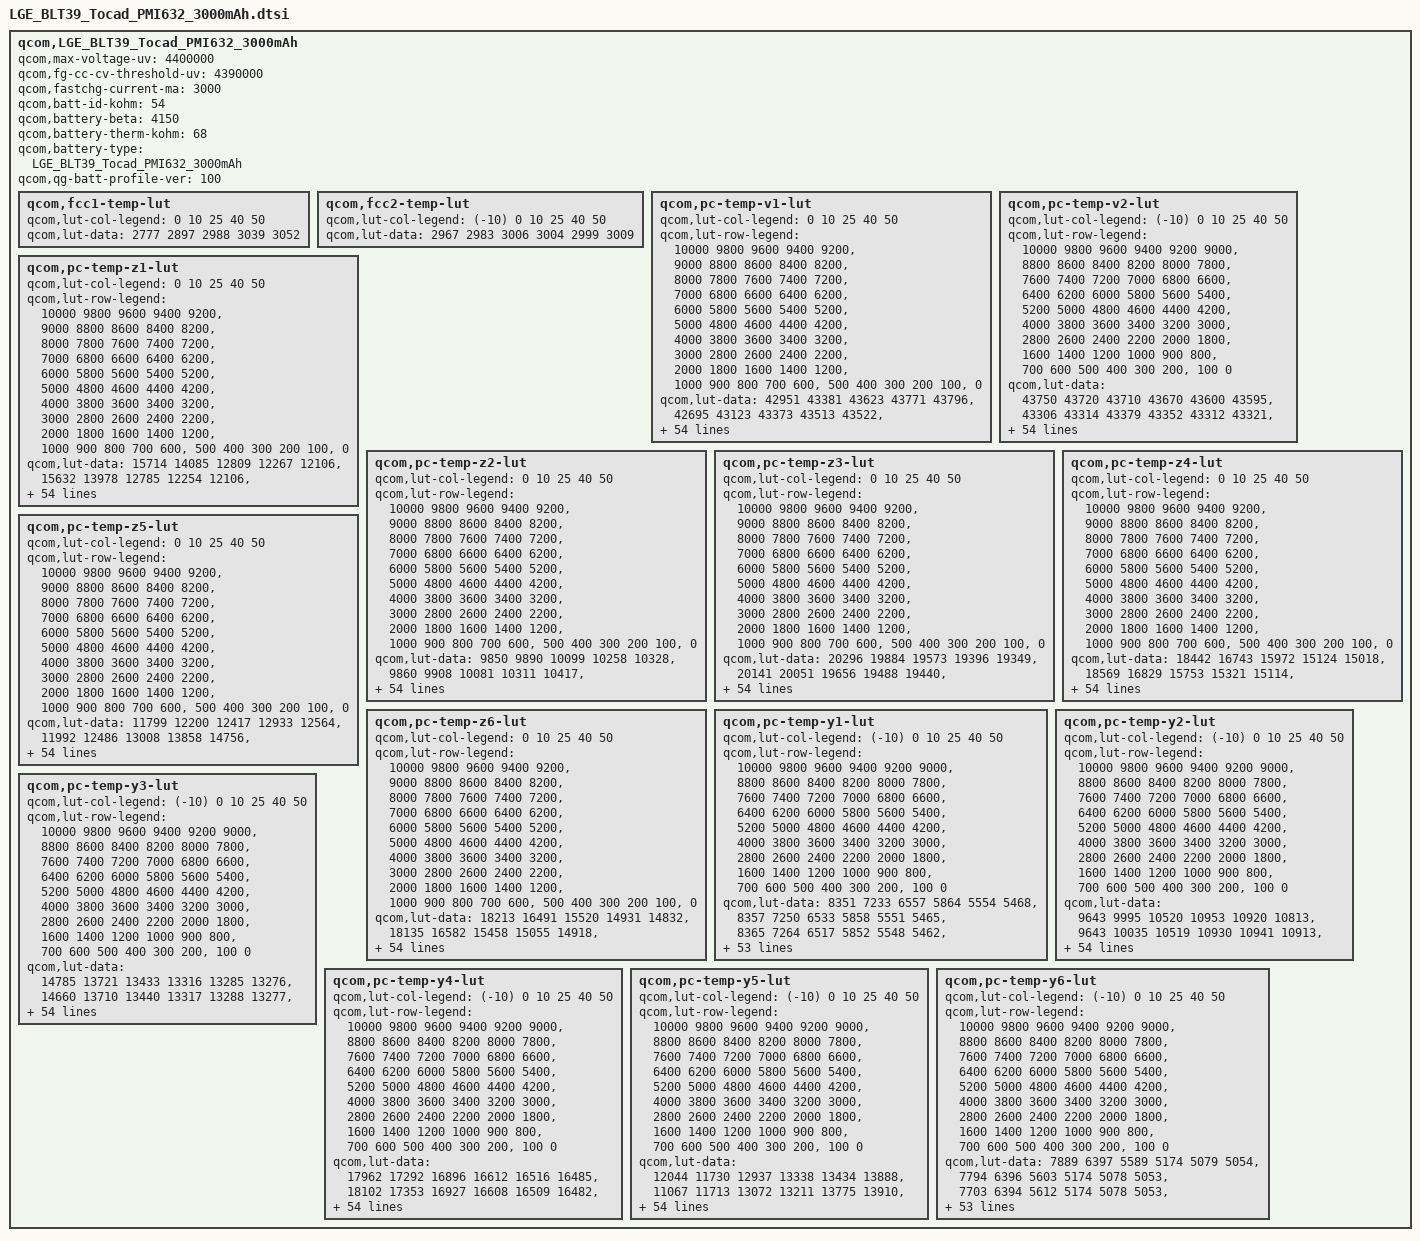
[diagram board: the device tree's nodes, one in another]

qcom,LGE_BLT39_Tocad_PMI632_3000mAh {
    /* 3869834_LGE_BLT39atl_3000mAh_averaged_MasterSlave_Feb20th2019 */
    qcom,max-voltage-uv = <4400000>;
    qcom,fg-cc-cv-threshold-uv = <4390000>;
    qcom,fastchg-current-ma = <3000>;
    qcom,batt-id-kohm = <54>;
    qcom,battery-beta = <4150>;
    qcom,battery-therm-kohm = <68>;
    qcom,battery-type = "LGE_BLT39_Tocad_PMI632_3000mAh";
    qcom,qg-batt-profile-ver = <100>;

	qcom,fcc1-temp-lut {
		qcom,lut-col-legend = <0 10 25 40 50>;
		qcom,lut-data = <2777 2897 2988 3039 3052>;
	};

	qcom,fcc2-temp-lut {
		qcom,lut-col-legend = <(-10) 0 10 25 40 50>;
		qcom,lut-data = <2967 2983 3006 3004 2999 3009>;
	};

	qcom,pc-temp-v1-lut {
		qcom,lut-col-legend = <0 10 25 40 50>;
		qcom,lut-row-legend = <10000 9800 9600 9400 9200>,
			<9000 8800 8600 8400 8200>,
			<8000 7800 7600 7400 7200>,
			<7000 6800 6600 6400 6200>,
			<6000 5800 5600 5400 5200>,
			<5000 4800 4600 4400 4200>,
			<4000 3800 3600 3400 3200>,
			<3000 2800 2600 2400 2200>,
			<2000 1800 1600 1400 1200>,
			<1000 900 800 700 600>,
			<500 400 300 200 100>,
			<0>;
		qcom,lut-data = <42951 43381 43623 43771 43796>,
			<42695 43123 43373 43513 43522>,
			<42449 42883 43126 43271 43280>,
			<42209 42651 42885 43035 43048>,
			<41979 42422 42647 42798 42815>,
			<41758 42196 42412 42561 42583>,
			<41545 41974 42180 42327 42350>,
			<41343 41754 41951 42094 42115>,
			<41159 41539 41724 41863 41882>,
			<40978 41334 41500 41634 41654>,
			<40774 41143 41282 41407 41429>,
			<40540 40950 41073 41187 41210>,
			<40315 40734 40869 40972 40994>,
			<40123 40504 40666 40766 40786>,
			<39947 40301 40463 40565 40581>,
			<39797 40124 40272 40372 40383>,
			<39672 39964 40100 40188 40196>,
			<39561 39819 39936 40012 40019>,
			<39454 39687 39779 39844 39849>,
			<39349 39555 39630 39694 39695>,
			<39250 39419 39477 39542 39544>,
			<39153 39281 39322 39343 39349>,
			<39058 39141 39158 39088 39083>,
			<38969 38998 38959 38878 38862>,
			<38888 38853 38715 38727 38730>,
			<38811 38695 38546 38605 38626>,
			<38731 38538 38466 38508 38525>,
			<38643 38429 38408 38430 38428>,
			<38556 38356 38356 38353 38339>,
			<38475 38303 38314 38273 38253>,
			<38390 38272 38270 38199 38176>,
			<38323 38251 38217 38137 38109>,
			<38281 38230 38164 38083 38052>,
			<38250 38207 38120 38033 37998>,
			<38219 38183 38084 37990 37951>,
			<38190 38157 38047 37947 37903>,
			<38158 38130 38010 37903 37845>,
			<38118 38093 37969 37856 37779>,
			<38064 38031 37908 37795 37706>,
			<37996 37939 37813 37708 37627>,
			<37898 37836 37706 37605 37538>,
			<37762 37712 37592 37494 37428>,
			<37614 37570 37461 37366 37297>,
			<37460 37400 37298 37206 37138>,
			<37342 37260 37152 37058 36994>,
			<37238 37163 37066 36972 36909>,
			<37202 37134 37040 36950 36891>,
			<37171 37109 37024 36936 36876>,
			<37139 37081 37002 36918 36857>,
			<37068 37030 36955 36871 36803>,
			<36840 36807 36720 36628 36534>,
			<36388 36359 36285 36197 36096>,
			<35813 35786 35713 35628 35520>,
			<35039 35003 34933 34851 34733>,
			<33776 33770 33713 33650 33503>,
			<30000 30000 30000 30000 30000>;
	};

	qcom,pc-temp-v2-lut {
		qcom,lut-col-legend = <(-10) 0 10 25 40 50>;
		qcom,lut-row-legend = <10000 9800 9600 9400 9200 9000>,
			<8800 8600 8400 8200 8000 7800>,
			<7600 7400 7200 7000 6800 6600>,
			<6400 6200 6000 5800 5600 5400>,
			<5200 5000 4800 4600 4400 4200>,
			<4000 3800 3600 3400 3200 3000>,
			<2800 2600 2400 2200 2000 1800>,
			<1600 1400 1200 1000 900 800>,
			<700 600 500 400 300 200>,
			<100 0>;
		qcom,lut-data = <43750 43720 43710 43670 43600 43595>,
			<43306 43314 43379 43352 43312 43321>,
			<42915 42955 43073 43059 43041 43059>,
			<42583 42651 42797 42796 42789 42811>,
			<42299 42391 42550 42559 42555 42577>,
			<42046 42152 42311 42329 42326 42346>,
			<41815 41930 42070 42097 42095 42115>,
			<41603 41718 41834 41868 41867 41886>,
			<41405 41484 41604 41644 41643 41661>,
			<41222 41219 41378 41424 41421 41437>,
			<41034 40990 41163 41209 41203 41218>,
			<40833 40842 40968 40997 40989 41005>,
			<40617 40717 40779 40789 40779 40796>,
			<40350 40518 40574 40585 40578 40595>,
			<39984 40187 40353 40380 40383 40397>,
			<39645 39872 40138 40186 40195 40207>,
			<39430 39666 39942 40011 40018 40028>,
			<39261 39493 39750 39844 39847 39855>,
			<39093 39308 39547 39682 39684 39691>,
			<38921 39111 39331 39531 39533 39538>,
			<38760 38922 39128 39360 39364 39367>,
			<38611 38749 38942 39127 39137 39141>,
			<38473 38588 38771 38880 38894 38907>,
			<38360 38440 38621 38702 38717 38733>,
			<38268 38294 38486 38565 38582 38593>,
			<38190 38180 38366 38447 38466 38472>,
			<38125 38110 38262 38342 38362 38367>,
			<38069 38058 38167 38249 38269 38274>,
			<38014 38009 38073 38162 38184 38187>,
			<37960 37966 37979 38083 38106 38106>,
			<37908 37925 37907 38012 38035 38033>,
			<37854 37881 37859 37944 37970 37967>,
			<37801 37837 37821 37883 37911 37905>,
			<37744 37790 37784 37823 37849 37845>,
			<37685 37741 37752 37768 37789 37790>,
			<37624 37690 37715 37713 37721 37720>,
			<37560 37636 37672 37660 37636 37611>,
			<37496 37578 37623 37604 37541 37489>,
			<37431 37513 37567 37541 37459 37398>,
			<37368 37438 37506 37470 37387 37323>,
			<37304 37355 37429 37389 37308 37241>,
			<37239 37255 37308 37286 37210 37143>,
			<37172 37143 37172 37166 37095 37029>,
			<37097 37034 37035 37018 36950 36891>,
			<37012 36936 36902 36897 36841 36781>,
			<36905 36849 36816 36839 36798 36747>,
			<36846 36807 36784 36826 36785 36737>,
			<36775 36767 36752 36803 36767 36719>,
			<36685 36718 36707 36772 36738 36682>,
			<36555 36637 36624 36684 36656 36567>,
			<36334 36442 36416 36389 36357 36231>,
			<35963 36037 35982 35887 35877 35724>,
			<35400 35432 35367 35250 35253 35067>,
			<34548 34578 34528 34357 34386 34157>,
			<33078 33229 33255 32986 33060 32722>,
			<28333 28048 27993 28115 29232 28098>;
	};

	qcom,pc-temp-z1-lut {
		qcom,lut-col-legend = <0 10 25 40 50>;
		qcom,lut-row-legend = <10000 9800 9600 9400 9200>,
			<9000 8800 8600 8400 8200>,
			<8000 7800 7600 7400 7200>,
			<7000 6800 6600 6400 6200>,
			<6000 5800 5600 5400 5200>,
			<5000 4800 4600 4400 4200>,
			<4000 3800 3600 3400 3200>,
			<3000 2800 2600 2400 2200>,
			<2000 1800 1600 1400 1200>,
			<1000 900 800 700 600>,
			<500 400 300 200 100>,
			<0>;
		qcom,lut-data = <15714 14085 12809 12267 12106>,
			<15632 13978 12785 12254 12106>,
			<15579 13970 12765 12243 12102>,
			<15532 13966 12749 12232 12098>,
			<15503 13956 12736 12225 12097>,
			<15495 13939 12724 12219 12096>,
			<15494 13927 12712 12216 12095>,
			<15492 13922 12704 12214 12093>,
			<15474 13920 12703 12213 12092>,
			<15444 13923 12703 12212 12092>,
			<15409 13937 12703 12211 12093>,
			<15344 13950 12702 12211 12093>,
			<15278 13940 12702 12211 12094>,
			<15237 13914 12700 12211 12096>,
			<15203 13897 12695 12211 12098>,
			<15174 13888 12693 12212 12099>,
			<15148 13881 12698 12214 12101>,
			<15127 13884 12705 12217 12104>,
			<15111 13894 12708 12220 12106>,
			<15099 13907 12710 12222 12109>,
			<15091 13922 12714 12225 12112>,
			<15096 13937 12721 12228 12114>,
			<15116 13941 12729 12231 12117>,
			<15140 13936 12733 12235 12120>,
			<15173 13933 12736 12240 12124>,
			<15215 13944 12740 12245 12129>,
			<15239 13965 12751 12250 12134>,
			<15257 13980 12763 12255 12139>,
			<15271 13990 12769 12261 12144>,
			<15273 13996 12772 12267 12150>,
			<15280 13991 12775 12273 12155>,
			<15292 13977 12780 12279 12159>,
			<15333 13971 12786 12284 12163>,
			<15402 13978 12792 12288 12167>,
			<15438 13987 12798 12292 12170>,
			<15443 13996 12804 12296 12173>,
			<15441 14006 12810 12301 12177>,
			<15440 14016 12816 12305 12180>,
			<15433 14028 12825 12310 12183>,
			<15427 14041 12839 12315 12187>,
			<15433 14054 12850 12320 12191>,
			<15446 14073 12856 12326 12195>,
			<15425 14080 12861 12331 12199>,
			<15381 14076 12867 12338 12203>,
			<15370 14053 12882 12346 12209>,
			<15357 14038 12892 12351 12214>,
			<15364 14052 12884 12353 12215>,
			<15332 14017 12890 12356 12217>,
			<15336 14021 12894 12360 12221>,
			<15375 14026 12904 12365 12226>,
			<15384 14058 12907 12375 12233>,
			<15365 14093 12930 12387 12245>,
			<15406 14129 12974 12408 12262>,
			<15420 14198 13009 12435 12284>,
			<15420 14198 13009 12435 12284>,
			<15420 14198 13009 12435 12284>;
	};

	qcom,pc-temp-z2-lut {
		qcom,lut-col-legend = <0 10 25 40 50>;
		qcom,lut-row-legend = <10000 9800 9600 9400 9200>,
			<9000 8800 8600 8400 8200>,
			<8000 7800 7600 7400 7200>,
			<7000 6800 6600 6400 6200>,
			<6000 5800 5600 5400 5200>,
			<5000 4800 4600 4400 4200>,
			<4000 3800 3600 3400 3200>,
			<3000 2800 2600 2400 2200>,
			<2000 1800 1600 1400 1200>,
			<1000 900 800 700 600>,
			<500 400 300 200 100>,
			<0>;
		qcom,lut-data = <9850 9890 10099 10258 10328>,
			<9860 9908 10081 10311 10417>,
			<9859 9913 10060 10290 10404>,
			<9849 9918 10032 10260 10381>,
			<9840 9933 9996 10225 10358>,
			<9838 9974 9980 10186 10329>,
			<9836 9999 9980 10180 10318>,
			<9835 9997 9980 10202 10335>,
			<9833 9992 9986 10228 10358>,
			<9830 9984 10002 10248 10370>,
			<9823 9963 10018 10267 10381>,
			<9805 9936 10031 10281 10379>,
			<9791 9900 10044 10295 10307>,
			<9791 9857 10059 10301 10241>,
			<9792 9842 10076 10270 10242>,
			<9794 9843 10090 10220 10254>,
			<9800 9846 10098 10216 10271>,
			<9808 9852 10106 10236 10305>,
			<9816 9867 10117 10248 10327>,
			<9824 9881 10131 10238 10323>,
			<9833 9891 10138 10226 10314>,
			<9845 9901 10139 10249 10325>,
			<9861 9910 10140 10339 10401>,
			<9880 9919 10134 10383 10452>,
			<9907 9927 10108 10290 10402>,
			<9939 9933 10095 10177 10329>,
			<9959 9939 10100 10219 10349>,
			<9981 9944 10111 10394 10482>,
			<9997 9952 10130 10470 10551>,
			<9989 9959 10168 10427 10473>,
			<9960 9962 10192 10369 10371>,
			<9931 9963 10200 10335 10342>,
			<9911 9965 10204 10307 10320>,
			<9893 9969 10201 10301 10313>,
			<9883 9974 10186 10333 10331>,
			<9877 9980 10177 10376 10363>,
			<9873 9988 10185 10406 10439>,
			<9877 9996 10202 10433 10580>,
			<9907 10006 10223 10463 10626>,
			<9936 10016 10256 10502 10574>,
			<9945 10027 10275 10528 10517>,
			<9951 10037 10275 10530 10493>,
			<9990 10051 10275 10531 10480>,
			<10047 10075 10292 10535 10490>,
			<9672 10250 10359 10558 10499>,
			<9668 10324 10390 10503 10496>,
			<9757 10394 10370 10467 10505>,
			<9775 10510 10395 10449 10483>,
			<9858 10578 10383 10445 10486>,
			<9922 10618 10390 10510 10631>,
			<9821 10545 10634 10783 10599>,
			<9652 10556 10603 10701 10491>,
			<9565 10286 10574 10650 10423>,
			<9400 10121 10523 10603 10333>,
			<9400 10121 10523 10603 10333>,
			<9400 10121 10523 10603 10333>;
	};

	qcom,pc-temp-z3-lut {
		qcom,lut-col-legend = <0 10 25 40 50>;
		qcom,lut-row-legend = <10000 9800 9600 9400 9200>,
			<9000 8800 8600 8400 8200>,
			<8000 7800 7600 7400 7200>,
			<7000 6800 6600 6400 6200>,
			<6000 5800 5600 5400 5200>,
			<5000 4800 4600 4400 4200>,
			<4000 3800 3600 3400 3200>,
			<3000 2800 2600 2400 2200>,
			<2000 1800 1600 1400 1200>,
			<1000 900 800 700 600>,
			<500 400 300 200 100>,
			<0>;
		qcom,lut-data = <20296 19884 19573 19396 19349>,
			<20141 20051 19656 19488 19440>,
			<20123 20068 19711 19524 19468>,
			<20142 20076 19726 19540 19480>,
			<20163 20057 19734 19545 19479>,
			<20178 19965 19736 19547 19470>,
			<20193 19887 19724 19545 19462>,
			<20198 19857 19702 19521 19457>,
			<20197 19836 19680 19498 19452>,
			<20197 19834 19655 19491 19443>,
			<20196 19848 19635 19486 19430>,
			<20196 19870 19621 19478 19414>,
			<20196 19900 19608 19465 19393>,
			<20186 19938 19595 19449 19378>,
			<20157 19951 19580 19423 19374>,
			<20122 19922 19568 19398 19373>,
			<20078 19880 19561 19393 19369>,
			<20024 19853 19555 19393 19358>,
			<19961 19830 19552 19393 19351>,
			<19878 19820 19550 19391 19351>,
			<19795 19823 19549 19390 19351>,
			<19731 19831 19558 19399 19356>,
			<19674 19842 19571 19437 19383>,
			<19629 19862 19577 19456 19400>,
			<19594 19881 19581 19437 19376>,
			<19565 19894 19583 19410 19341>,
			<19563 19904 19574 19396 19341>,
			<19734 19907 19559 19384 19364>,
			<19928 19903 19548 19382 19387>,
			<20003 19896 19538 19429 19409>,
			<20204 19886 19533 19480 19426>,
			<20342 19869 19560 19480 19424>,
			<20325 19853 19596 19468 19408>,
			<20289 19842 19599 19456 19396>,
			<20250 19832 19588 19445 19386>,
			<20204 19820 19575 19435 19379>,
			<20151 19804 19566 19428 19380>,
			<20089 19793 19558 19422 19383>,
			<20007 19789 19552 19419 19383>,
			<19949 19786 19548 19416 19376>,
			<19942 19782 19544 19413 19367>,
			<19945 19764 19539 19408 19364>,
			<19926 19743 19532 19402 19361>,
			<19850 19719 19521 19398 19358>,
			<19275 19608 19496 19394 19354>,
			<19267 19565 19471 19378 19353>,
			<19265 19516 19469 19376 19345>,
			<19264 19465 19448 19362 19341>,
			<19264 19445 19447 19361 19339>,
			<19263 19444 19443 19353 19329>,
			<19264 19473 19391 19326 19331>,
			<19266 19438 19368 19332 19338>,
			<19268 19377 19357 19328 19344>,
			<19273 19376 19349 19326 19351>,
			<19273 19376 19349 19326 19351>,
			<19273 19376 19349 19326 19351>;
	};

	qcom,pc-temp-z4-lut {
		qcom,lut-col-legend = <0 10 25 40 50>;
		qcom,lut-row-legend = <10000 9800 9600 9400 9200>,
			<9000 8800 8600 8400 8200>,
			<8000 7800 7600 7400 7200>,
			<7000 6800 6600 6400 6200>,
			<6000 5800 5600 5400 5200>,
			<5000 4800 4600 4400 4200>,
			<4000 3800 3600 3400 3200>,
			<3000 2800 2600 2400 2200>,
			<2000 1800 1600 1400 1200>,
			<1000 900 800 700 600>,
			<500 400 300 200 100>,
			<0>;
		qcom,lut-data = <18442 16743 15972 15124 15018>,
			<18569 16829 15753 15321 15114>,
			<18469 16568 15569 15227 15068>,
			<17967 16188 15422 15114 14995>,
			<17437 15998 15299 15043 14943>,
			<17107 15889 15201 14984 14899>,
			<16827 15791 15118 14946 14869>,
			<16598 15691 15053 14920 14850>,
			<16407 15594 15013 14899 14836>,
			<16248 15491 14986 14875 14825>,
			<16129 15376 14963 14853 14816>,
			<16037 15268 14942 14837 14810>,
			<15958 15173 14924 14823 14807>,
			<15885 15087 14911 14816 14804>,
			<15819 15049 14901 14817 14792>,
			<15764 15038 14889 14819 14772>,
			<15711 15031 14867 14815 14758>,
			<15670 15015 14842 14791 14748>,
			<15665 14992 14825 14769 14739>,
			<15705 14969 14811 14754 14726>,
			<15757 14945 14806 14743 14713>,
			<15800 14925 14810 14761 14728>,
			<15845 14922 14820 14846 14833>,
			<15877 14923 14869 14920 14922>,
			<15896 14926 15022 14974 14953>,
			<15909 14966 15103 15010 14972>,
			<15899 15045 15094 15009 14964>,
			<15698 15071 15075 14992 14913>,
			<15474 15068 15052 14965 14860>,
			<15385 15061 15021 14887 14809>,
			<15156 15046 14983 14808 14765>,
			<14990 15014 14927 14783 14747>,
			<14983 14984 14872 14768 14736>,
			<14980 14960 14849 14763 14732>,
			<14979 14939 14837 14762 14731>,
			<14988 14921 14831 14761 14731>,
			<15003 14903 14829 14765 14742>,
			<15023 14891 14827 14777 14770>,
			<15054 14885 14832 14790 14784>,
			<15077 14881 14856 14809 14789>,
			<15058 14877 14871 14821 14791>,
			<15014 14873 14853 14812 14784>,
			<14994 14870 14833 14799 14773>,
			<14984 14865 14830 14801 14779>,
			<15352 14847 14803 14788 14774>,
			<15348 14842 14767 14761 14744>,
			<15338 14876 14749 14741 14727>,
			<15327 14914 14739 14721 14699>,
			<15314 14923 14721 14692 14671>,
			<15294 14917 14723 14706 14691>,
			<15295 14897 14820 14781 14728>,
			<15338 14965 14859 14780 14723>,
			<15371 15054 14877 14785 14716>,
			<15400 15075 14891 14789 14710>,
			<15400 15075 14891 14789 14710>,
			<15400 15075 14891 14789 14710>;
	};

	qcom,pc-temp-z5-lut {
		qcom,lut-col-legend = <0 10 25 40 50>;
		qcom,lut-row-legend = <10000 9800 9600 9400 9200>,
			<9000 8800 8600 8400 8200>,
			<8000 7800 7600 7400 7200>,
			<7000 6800 6600 6400 6200>,
			<6000 5800 5600 5400 5200>,
			<5000 4800 4600 4400 4200>,
			<4000 3800 3600 3400 3200>,
			<3000 2800 2600 2400 2200>,
			<2000 1800 1600 1400 1200>,
			<1000 900 800 700 600>,
			<500 400 300 200 100>,
			<0>;
		qcom,lut-data = <11799 12200 12417 12933 12564>,
			<11992 12486 13008 13858 14756>,
			<12316 12681 13491 14415 15453>,
			<12819 12809 13837 14790 15824>,
			<13336 12785 14103 15150 15974>,
			<13766 12604 14351 15439 16064>,
			<14170 12487 14622 15495 16193>,
			<14550 12512 14857 15453 16485>,
			<14939 12580 15017 15420 16729>,
			<15280 12691 15175 15654 16638>,
			<15496 12998 15236 16070 16271>,
			<15667 13476 15356 16147 15823>,
			<15760 14465 15512 16013 15103>,
			<15740 15958 15525 15797 14585>,
			<15656 16488 15509 15119 14774>,
			<15532 16000 15573 14266 15222>,
			<15256 15452 16002 14219 15337>,
			<14817 15441 16711 14778 15214>,
			<14305 15702 17413 15417 15117>,
			<13584 16104 18197 15856 15407>,
			<12887 16946 19301 16426 16270>,
			<12441 18371 21708 19564 18306>,
			<12091 20380 24477 28881 24309>,
			<11833 23829 26024 33422 27991>,
			<11641 27241 27192 27465 23027>,
			<11492 29926 27617 19346 15564>,
			<11700 32225 25181 16300 14221>,
			<15800 32799 21360 14512 14175>,
			<20356 31799 19192 14056 14331>,
			<22161 30213 17587 16228 16203>,
			<27088 28429 16959 19265 18717>,
			<30595 26169 19318 21156 19799>,
			<29677 24669 22950 22697 20613>,
			<27228 23988 24497 23731 21191>,
			<24848 23487 25348 24527 22226>,
			<22406 22998 25739 24971 23142>,
			<19945 22468 25853 24682 23111>,
			<18007 22191 25909 23717 22750>,
			<16167 22941 25634 22529 22132>,
			<15099 24343 24301 20700 19735>,
			<15599 24573 23176 19121 17495>,
			<16748 22826 22753 18502 17088>,
			<16946 21768 22323 18035 16858>,
			<16525 21125 20763 17120 15875>,
			<11144 18519 20960 17294 15631>,
			<11044 16877 20168 17036 16460>,
			<11002 14701 20302 17394 16119>,
			<10989 13235 18091 16627 16981>,
			<10993 12896 18582 17926 19097>,
			<11028 12939 18240 16523 16410>,
			<11071 13751 13819 12926 13734>,
			<11062 12692 12739 12774 13779>,
			<10967 11752 12312 12481 13937>,
			<10903 11584 12006 12275 14288>,
			<10903 11584 12006 12275 14288>,
			<10903 11584 12006 12275 14288>;
	};

	qcom,pc-temp-z6-lut {
		qcom,lut-col-legend = <0 10 25 40 50>;
		qcom,lut-row-legend = <10000 9800 9600 9400 9200>,
			<9000 8800 8600 8400 8200>,
			<8000 7800 7600 7400 7200>,
			<7000 6800 6600 6400 6200>,
			<6000 5800 5600 5400 5200>,
			<5000 4800 4600 4400 4200>,
			<4000 3800 3600 3400 3200>,
			<3000 2800 2600 2400 2200>,
			<2000 1800 1600 1400 1200>,
			<1000 900 800 700 600>,
			<500 400 300 200 100>,
			<0>;
		qcom,lut-data = <18213 16491 15520 14931 14832>,
			<18135 16582 15458 15055 14918>,
			<17989 16462 15399 15030 14908>,
			<17741 16271 15343 14996 14889>,
			<17502 16138 15289 14971 14868>,
			<17336 16029 15239 14946 14845>,
			<17194 15937 15192 14923 14827>,
			<17076 15863 15151 14899 14816>,
			<16977 15801 15120 14878 14807>,
			<16892 15747 15094 14864 14796>,
			<16814 15701 15074 14852 14785>,
			<16745 15662 15057 14840 14774>,
			<16681 15632 15042 14827 14763>,
			<16622 15607 15028 14815 14753>,
			<16566 15585 15015 14803 14744>,
			<16512 15565 15002 14792 14735>,
			<16453 15547 14988 14782 14727>,
			<16399 15528 14976 14772 14718>,
			<16362 15510 14968 14765 14710>,
			<16334 15499 14962 14758 14704>,
			<16316 15496 14959 14752 14699>,
			<16307 15494 14965 14766 14709>,
			<16302 15495 14977 14825 14773>,
			<16300 15505 15007 14863 14815>,
			<16300 15521 15076 14874 14813>,
			<16301 15551 15110 14879 14809>,
			<16304 15592 15103 14876 14804>,
			<16318 15604 15090 14863 14797>,
			<16332 15603 15075 14852 14789>,
			<16337 15600 15057 14844 14780>,
			<16351 15591 15043 14837 14771>,
			<16360 15569 15036 14827 14760>,
			<16356 15550 15030 14816 14749>,
			<16346 15537 15023 14807 14740>,
			<16336 15526 15013 14799 14735>,
			<16325 15515 15005 14794 14731>,
			<16313 15504 15001 14795 14736>,
			<16300 15498 14998 14797 14751>,
			<16286 15499 15000 14800 14756>,
			<16272 15501 15010 14807 14755>,
			<16261 15501 15017 14812 14752>,
			<16249 15497 15009 14807 14748>,
			<16229 15492 14999 14798 14743>,
			<16190 15485 14996 14798 14744>,
			<16063 15432 14977 14793 14741>,
			<16059 15414 14953 14774 14728>,
			<16054 15406 14945 14764 14717>,
			<16051 15399 14931 14749 14703>,
			<16050 15397 14925 14737 14690>,
			<16052 15401 14927 14739 14694>,
			<16067 15421 14947 14760 14714>,
			<16104 15443 14959 14766 14718>,
			<16142 15471 14970 14771 14721>,
			<16192 15507 14986 14778 14727>,
			<16192 15507 14986 14778 14727>,
			<16192 15507 14986 14778 14727>;
	};

	qcom,pc-temp-y1-lut {
		qcom,lut-col-legend = <(-10) 0 10 25 40 50>;
		qcom,lut-row-legend = <10000 9800 9600 9400 9200 9000>,
			<8800 8600 8400 8200 8000 7800>,
			<7600 7400 7200 7000 6800 6600>,
			<6400 6200 6000 5800 5600 5400>,
			<5200 5000 4800 4600 4400 4200>,
			<4000 3800 3600 3400 3200 3000>,
			<2800 2600 2400 2200 2000 1800>,
			<1600 1400 1200 1000 900 800>,
			<700 600 500 400 300 200>,
			<100 0>;
		qcom,lut-data = <8351 7233 6557 5864 5554 5468>,
			<8357 7250 6533 5858 5551 5465>,
			<8365 7264 6517 5852 5548 5462>,
			<8373 7274 6507 5846 5545 5460>,
			<8380 7280 6501 5842 5543 5458>,
			<8384 7282 6498 5840 5541 5456>,
			<8385 7278 6501 5841 5539 5456>,
			<8386 7271 6507 5843 5537 5457>,
			<8383 7272 6508 5842 5536 5456>,
			<8358 7285 6503 5834 5534 5453>,
			<8339 7294 6499 5828 5532 5451>,
			<8339 7288 6492 5826 5531 5451>,
			<8341 7277 6483 5824 5530 5451>,
			<8344 7276 6485 5823 5530 5451>,
			<8357 7288 6499 5821 5529 5452>,
			<8368 7299 6507 5820 5529 5453>,
			<8366 7304 6503 5822 5530 5453>,
			<8359 7307 6496 5826 5531 5454>,
			<8356 7307 6495 5829 5532 5456>,
			<8363 7297 6496 5830 5533 5457>,
			<8369 7288 6497 5831 5535 5458>,
			<8357 7288 6499 5832 5536 5459>,
			<8332 7287 6502 5834 5537 5459>,
			<8324 7287 6506 5837 5539 5460>,
			<8360 7289 6515 5844 5541 5463>,
			<8398 7290 6521 5849 5543 5465>,
			<8382 7300 6523 5852 5546 5466>,
			<8332 7317 6525 5854 5550 5468>,
			<8308 7321 6526 5857 5552 5470>,
			<8304 7312 6529 5863 5554 5473>,
			<8302 7304 6530 5869 5557 5476>,
			<8305 7298 6527 5873 5562 5479>,
			<8320 7287 6524 5877 5568 5482>,
			<8326 7284 6527 5882 5573 5484>,
			<8314 7287 6539 5889 5578 5488>,
			<8297 7289 6547 5895 5582 5491>,
			<8295 7287 6554 5901 5585 5496>,
			<8305 7281 6560 5906 5588 5500>,
			<8311 7279 6559 5911 5591 5501>,
			<8312 7278 6549 5915 5594 5502>,
			<8315 7278 6544 5921 5599 5504>,
			<8324 7278 6546 5927 5604 5506>,
			<8349 7277 6551 5937 5609 5509>,
			<8330 7277 6562 5958 5614 5512>,
			<8277 7281 6560 5963 5618 5517>,
			<8297 7293 6566 5970 5622 5518>,
			<8336 7306 6580 5963 5623 5522>,
			<8325 7308 6587 5969 5627 5524>,
			<8351 7300 6588 5976 5631 5523>,
			<8331 7304 6575 5983 5633 5525>,
			<8336 7333 6593 6000 5637 5531>,
			<8405 7350 6608 6019 5649 5538>,
			<8408 7350 6608 6046 5665 5551>,
			<8497 7395 6645 6082 5686 5565>,
			<8497 7395 6645 6082 5686 5565>,
			<8497 7395 6645 6082 5686 5565>;
	};

	qcom,pc-temp-y2-lut {
		qcom,lut-col-legend = <(-10) 0 10 25 40 50>;
		qcom,lut-row-legend = <10000 9800 9600 9400 9200 9000>,
			<8800 8600 8400 8200 8000 7800>,
			<7600 7400 7200 7000 6800 6600>,
			<6400 6200 6000 5800 5600 5400>,
			<5200 5000 4800 4600 4400 4200>,
			<4000 3800 3600 3400 3200 3000>,
			<2800 2600 2400 2200 2000 1800>,
			<1600 1400 1200 1000 900 800>,
			<700 600 500 400 300 200>,
			<100 0>;
		qcom,lut-data = <9643 9995 10520 10953 10920 10813>,
			<9643 10035 10519 10930 10941 10913>,
			<9643 10090 10516 10894 10955 10969>,
			<9723 10145 10510 10855 10961 10993>,
			<9847 10188 10504 10822 10962 10996>,
			<9965 10206 10496 10804 10956 10989>,
			<10093 10200 10486 10799 10941 10950>,
			<10209 10189 10476 10795 10921 10896>,
			<10252 10211 10473 10785 10910 10881>,
			<10266 10354 10472 10758 10901 10882>,
			<10278 10456 10473 10742 10896 10891>,
			<10298 10420 10496 10746 10896 10933>,
			<10320 10355 10536 10755 10903 10987>,
			<10288 10348 10565 10764 10916 11004>,
			<9956 10404 10588 10784 10944 11001>,
			<9673 10465 10607 10807 10976 11004>,
			<9663 10499 10623 10838 11004 11037>,
			<9662 10528 10636 10869 11035 11089>,
			<9661 10557 10644 10886 11080 11133>,
			<9661 10591 10649 10899 11153 11182>,
			<9660 10610 10656 10905 11192 11205>,
			<9660 10605 10676 10897 11137 11144>,
			<9659 10587 10704 10885 11051 11062>,
			<9658 10509 10725 10890 11033 11055>,
			<9658 10073 10742 10926 11033 11079>,
			<9658 9717 10755 10960 11034 11103>,
			<9657 9699 10763 10982 11062 11122>,
			<9656 9693 10770 11000 11109 11142>,
			<9656 9686 10792 11010 11140 11163>,
			<9655 9678 10844 11019 11194 11191>,
			<9655 9671 10871 11023 11229 11218>,
			<9654 9667 10853 11022 11246 11243>,
			<9654 9664 10819 11019 11266 11272>,
			<9653 9661 10789 11014 11264 11318>,
			<9653 9658 10756 11000 11248 11391>,
			<9653 9657 10705 10987 11225 11423>,
			<9653 9655 10486 10978 11180 11320>,
			<9652 9654 10226 10969 11127 11191>,
			<9652 9653 10227 10958 11110 11177>,
			<9652 9653 10421 10943 11106 11192>,
			<9652 9652 10500 10922 11101 11202>,
			<9652 9652 10076 10893 11086 11200>,
			<9652 9652 9729 10855 11071 11198>,
			<9652 9651 9679 10802 11084 11214>,
			<9652 9651 9668 10736 11058 11151>,
			<9652 9651 9667 10739 11052 11045>,
			<9651 9651 9665 10717 11035 11039>,
			<9651 9651 9662 10700 11041 11048>,
			<9651 9651 9660 10681 11061 11019>,
			<9651 9651 9658 10666 11005 11000>,
			<9651 9650 9657 10600 10984 10985>,
			<9651 9650 9654 10513 10919 10918>,
			<9650 9650 9652 10457 10828 10847>,
			<9649 9650 9651 10373 10724 10788>,
			<9649 9650 9651 10373 10724 10788>,
			<9649 9650 9651 10373 10724 10788>;
	};

	qcom,pc-temp-y3-lut {
		qcom,lut-col-legend = <(-10) 0 10 25 40 50>;
		qcom,lut-row-legend = <10000 9800 9600 9400 9200 9000>,
			<8800 8600 8400 8200 8000 7800>,
			<7600 7400 7200 7000 6800 6600>,
			<6400 6200 6000 5800 5600 5400>,
			<5200 5000 4800 4600 4400 4200>,
			<4000 3800 3600 3400 3200 3000>,
			<2800 2600 2400 2200 2000 1800>,
			<1600 1400 1200 1000 900 800>,
			<700 600 500 400 300 200>,
			<100 0>;
		qcom,lut-data = <14785 13721 13433 13316 13285 13276>,
			<14660 13710 13440 13317 13288 13277>,
			<14464 13705 13447 13318 13290 13279>,
			<14254 13705 13454 13319 13292 13280>,
			<14083 13708 13460 13320 13294 13282>,
			<14008 13714 13465 13320 13295 13283>,
			<14021 13732 13469 13320 13297 13284>,
			<14046 13756 13472 13320 13298 13285>,
			<14026 13744 13475 13321 13299 13285>,
			<13836 13636 13477 13331 13299 13285>,
			<13687 13560 13478 13338 13300 13285>,
			<13705 13573 13472 13338 13299 13289>,
			<13746 13596 13462 13337 13297 13294>,
			<13751 13600 13459 13337 13298 13294>,
			<13697 13593 13458 13338 13302 13292>,
			<13644 13582 13456 13339 13306 13291>,
			<13632 13567 13452 13339 13309 13293>,
			<13625 13549 13444 13339 13311 13297>,
			<13617 13530 13436 13340 13312 13298>,
			<13605 13511 13424 13346 13312 13300>,
			<13593 13494 13414 13350 13312 13300>,
			<13579 13483 13405 13343 13305 13294>,
			<13565 13472 13398 13331 13295 13286>,
			<13561 13446 13392 13324 13291 13282>,
			<13564 13358 13385 13319 13290 13280>,
			<13571 13291 13380 13317 13289 13279>,
			<13588 13293 13379 13316 13288 13279>,
			<13628 13303 13378 13315 13287 13279>,
			<13671 13316 13371 13316 13287 13279>,
			<13718 13339 13352 13317 13289 13279>,
			<13772 13368 13342 13319 13291 13280>,
			<13835 13400 13345 13320 13292 13280>,
			<13907 13437 13351 13320 13293 13281>,
			<13980 13482 13357 13320 13293 13283>,
			<14054 13541 13368 13319 13294 13285>,
			<14128 13609 13376 13319 13294 13285>,
			<14201 13685 13374 13320 13292 13283>,
			<14274 13771 13371 13321 13288 13280>,
			<14346 13860 13378 13321 13287 13279>,
			<14417 13958 13397 13321 13287 13280>,
			<14489 14054 13409 13322 13287 13280>,
			<14564 14138 13409 13323 13286 13279>,
			<14643 14216 13410 13324 13286 13277>,
			<14725 14293 13424 13325 13286 13279>,
			<14807 14374 13430 13329 13288 13278>,
			<14877 14374 13447 13324 13291 13281>,
			<14731 14366 13473 13332 13290 13286>,
			<14843 14477 13517 13333 13291 13288>,
			<14959 14578 13573 13347 13301 13292>,
			<15088 14688 13643 13357 13309 13291>,
			<15234 14804 13717 13351 13300 13283>,
			<15434 14949 13822 13355 13304 13289>,
			<15689 15166 14050 13383 13316 13299>,
			<16719 15509 14395 13408 13320 13302>,
			<16719 15509 14395 13408 13320 13302>,
			<16719 15509 14395 13408 13320 13302>;
	};

	qcom,pc-temp-y4-lut {
		qcom,lut-col-legend = <(-10) 0 10 25 40 50>;
		qcom,lut-row-legend = <10000 9800 9600 9400 9200 9000>,
			<8800 8600 8400 8200 8000 7800>,
			<7600 7400 7200 7000 6800 6600>,
			<6400 6200 6000 5800 5600 5400>,
			<5200 5000 4800 4600 4400 4200>,
			<4000 3800 3600 3400 3200 3000>,
			<2800 2600 2400 2200 2000 1800>,
			<1600 1400 1200 1000 900 800>,
			<700 600 500 400 300 200>,
			<100 0>;
		qcom,lut-data = <17962 17292 16896 16612 16516 16485>,
			<18102 17353 16927 16608 16509 16482>,
			<18163 17438 16969 16608 16505 16480>,
			<18163 17527 17013 16610 16503 16479>,
			<18122 17597 17047 16615 16502 16479>,
			<18059 17626 17060 16621 16502 16479>,
			<17926 17618 17056 16630 16505 16482>,
			<17760 17603 17049 16641 16510 16488>,
			<17779 17624 17046 16644 16517 16495>,
			<18191 17780 17045 16644 16526 16504>,
			<18513 17919 17046 16646 16537 16510>,
			<18403 17974 17116 16658 16551 16513>,
			<18139 18011 17217 16680 16567 16515>,
			<17943 17964 17230 16702 16579 16521>,
			<17792 17603 17206 16726 16587 16539>,
			<17685 17320 17176 16754 16597 16556>,
			<17637 17300 17150 16789 16612 16566>,
			<17607 17291 17118 16827 16632 16577>,
			<17564 17264 17067 16855 16662 16598>,
			<17496 17185 16982 16880 16712 16633>,
			<17428 17092 16902 16890 16739 16650>,
			<17375 17001 16838 16787 16674 16606>,
			<17329 16917 16785 16631 16566 16539>,
			<17314 16905 16753 16584 16526 16509>,
			<17314 16973 16733 16568 16509 16490>,
			<17314 17029 16717 16563 16502 16483>,
			<17309 17032 16701 16567 16508 16487>,
			<17299 17033 16688 16575 16520 16496>,
			<17293 17033 16680 16584 16532 16507>,
			<17293 17033 16673 16594 16546 16521>,
			<17294 17033 16670 16604 16563 16537>,
			<17292 17034 16672 16617 16585 16555>,
			<17290 17037 16677 16628 16605 16571>,
			<17289 17042 16684 16629 16609 16582>,
			<17294 17053 16700 16624 16608 16591>,
			<17304 17065 16721 16618 16605 16594>,
			<17315 17074 16779 16607 16575 16556>,
			<17329 17081 16844 16596 16530 16508>,
			<17347 17084 16857 16594 16521 16500>,
			<17373 17083 16847 16596 16522 16498>,
			<17407 17080 16848 16598 16523 16497>,
			<17449 17066 16884 16604 16524 16498>,
			<17501 17043 16908 16613 16525 16499>,
			<17554 17043 16907 16622 16525 16500>,
			<17590 17048 16909 16612 16514 16487>,
			<17567 17044 16891 16604 16514 16496>,
			<17384 17047 16924 16634 16538 16506>,
			<17399 17090 16968 16677 16561 16517>,
			<17423 17152 17035 16719 16570 16525>,
			<17440 17213 17109 16735 16563 16521>,
			<17419 17203 17136 16700 16526 16498>,
			<17387 17130 17103 16698 16527 16497>,
			<17381 17109 17121 16741 16548 16506>,
			<17749 17155 17199 16829 16606 16570>,
			<17749 17155 17199 16829 16606 16570>,
			<17749 17155 17199 16829 16606 16570>;
	};

	qcom,pc-temp-y5-lut {
		qcom,lut-col-legend = <(-10) 0 10 25 40 50>;
		qcom,lut-row-legend = <10000 9800 9600 9400 9200 9000>,
			<8800 8600 8400 8200 8000 7800>,
			<7600 7400 7200 7000 6800 6600>,
			<6400 6200 6000 5800 5600 5400>,
			<5200 5000 4800 4600 4400 4200>,
			<4000 3800 3600 3400 3200 3000>,
			<2800 2600 2400 2200 2000 1800>,
			<1600 1400 1200 1000 900 800>,
			<700 600 500 400 300 200>,
			<100 0>;
		qcom,lut-data = <12044 11730 12937 13338 13434 13888>,
			<11067 11713 13072 13211 13775 13910>,
			<10716 11860 13296 13057 13982 13920>,
			<10848 12143 13540 12881 14089 13920>,
			<11320 12533 13737 12688 14128 13911>,
			<11990 13003 13816 12482 14134 13894>,
			<13275 13746 13806 12198 14008 13723>,
			<14803 14509 13784 11937 13739 13401>,
			<14948 14387 13763 11964 13461 13081>,
			<13462 12693 13722 12326 13130 12697>,
			<12300 11484 13652 12554 12786 12510>,
			<13628 12734 13171 12358 12378 12871>,
			<16263 14913 12528 12038 12019 13395>,
			<16673 15421 12675 11913 11989 13344>,
			<13655 15351 13968 11850 12159 12710>,
			<11090 15301 15035 11825 12294 12337>,
			<11091 15409 15479 11909 12325 12413>,
			<11260 15613 15776 12128 12349 12551>,
			<11314 15702 15910 12769 12424 12651>,
			<11293 15748 15996 14670 12676 12729>,
			<11253 15800 16043 15974 13048 12867>,
			<11137 15931 15973 16280 13922 13797>,
			<10897 16115 15842 16451 14937 14941>,
			<10704 15811 15703 16303 15118 15075>,
			<10543 12934 15314 15501 15084 14857>,
			<10441 10573 15099 14931 15024 14612>,
			<10459 10522 15435 14777 14603 14274>,
			<10524 10519 15893 14678 14009 13916>,
			<10556 10528 15504 14751 13933 13729>,
			<10582 10616 13562 15158 14158 13555>,
			<10620 10730 12430 15552 14420 13523>,
			<10675 10816 12556 15943 14666 13675>,
			<10765 10897 12821 16318 14970 13938>,
			<10803 10962 13077 16420 15368 14416>,
			<10790 11007 13614 16447 15951 15269>,
			<10768 11056 13948 16456 16264 15661>,
			<10740 11148 13581 16480 16010 15467>,
			<10701 11271 13061 16482 15497 15178>,
			<10679 11336 13333 16295 15055 15034>,
			<10673 11397 14453 15658 14628 14925>,
			<10670 11441 15016 15034 14244 14736>,
			<10678 11373 13295 14578 13862 13991>,
			<10723 11196 11803 14213 13644 13449>,
			<10799 11009 11603 13916 13671 13661>,
			<10938 10958 11304 14250 14403 14092>,
			<11098 11030 11351 13543 14348 13574>,
			<11190 11005 11341 13680 13123 14000>,
			<11291 11145 11416 12884 12535 13543>,
			<11368 11226 11510 12969 13041 13698>,
			<11457 11380 11595 13263 14075 13723>,
			<11443 11374 11574 13278 14021 13006>,
			<11182 11119 11426 13403 14777 14692>,
			<10907 10979 11325 14933 17360 17838>,
			<10251 10827 11351 15551 16952 17926>,
			<10251 10827 11351 15551 16952 17926>,
			<10251 10827 11351 15551 16952 17926>;
	};

	qcom,pc-temp-y6-lut {
		qcom,lut-col-legend = <(-10) 0 10 25 40 50>;
		qcom,lut-row-legend = <10000 9800 9600 9400 9200 9000>,
			<8800 8600 8400 8200 8000 7800>,
			<7600 7400 7200 7000 6800 6600>,
			<6400 6200 6000 5800 5600 5400>,
			<5200 5000 4800 4600 4400 4200>,
			<4000 3800 3600 3400 3200 3000>,
			<2800 2600 2400 2200 2000 1800>,
			<1600 1400 1200 1000 900 800>,
			<700 600 500 400 300 200>,
			<100 0>;
		qcom,lut-data = <7889 6397 5589 5174 5079 5054>,
			<7794 6396 5603 5174 5078 5053>,
			<7703 6394 5612 5174 5078 5053>,
			<7618 6391 5617 5174 5078 5054>,
			<7541 6388 5618 5175 5079 5055>,
			<7472 6384 5618 5176 5081 5056>,
			<7410 6380 5614 5178 5082 5058>,
			<7356 6374 5606 5179 5085 5060>,
			<7313 6362 5599 5182 5087 5062>,
			<7281 6327 5594 5186 5090 5064>,
			<7248 6304 5591 5191 5093 5066>,
			<7212 6319 5601 5196 5096 5070>,
			<7170 6346 5616 5200 5100 5073>,
			<7105 6338 5617 5206 5104 5077>,
			<6978 6239 5608 5213 5109 5080>,
			<6875 6155 5597 5221 5115 5084>,
			<6851 6139 5586 5231 5121 5089>,
			<6838 6130 5572 5241 5128 5094>,
			<6825 6114 5552 5251 5137 5101>,
			<6812 6086 5519 5262 5151 5112>,
			<6800 6059 5490 5266 5159 5117>,
			<6790 6039 5467 5232 5135 5100>,
			<6782 6022 5450 5179 5097 5075>,
			<6780 6013 5439 5162 5083 5063>,
			<6793 6005 5432 5154 5077 5056>,
			<6815 6002 5429 5152 5075 5054>,
			<6840 6015 5429 5153 5076 5055>,
			<6872 6051 5431 5156 5079 5058>,
			<6908 6089 5430 5159 5083 5061>,
			<6949 6134 5424 5165 5088 5065>,
			<6997 6184 5421 5170 5094 5070>,
			<7049 6238 5430 5176 5102 5076>,
			<7108 6298 5448 5181 5109 5082>,
			<7168 6365 5469 5182 5111 5087>,
			<7228 6443 5497 5182 5111 5091>,
			<7289 6526 5530 5182 5111 5092>,
			<7349 6610 5568 5182 5101 5080>,
			<7410 6696 5612 5181 5087 5064>,
			<7471 6780 5663 5182 5084 5062>,
			<7531 6865 5724 5185 5084 5062>,
			<7594 6943 5784 5190 5085 5062>,
			<7662 7008 5835 5197 5086 5062>,
			<7735 7065 5889 5205 5086 5062>,
			<7812 7126 5959 5215 5088 5063>,
			<7889 7191 6039 5221 5087 5060>,
			<7950 7195 6040 5216 5089 5064>,
			<7804 7195 6102 5235 5096 5071>,
			<7900 7291 6179 5252 5104 5076>,
			<7995 7387 6271 5279 5114 5081>,
			<8104 7489 6372 5298 5118 5080>,
			<8217 7577 6464 5291 5101 5069>,
			<8368 7677 6581 5310 5107 5073>,
			<8587 7844 6813 5366 5123 5085>,
			<9623 8154 7133 5439 5146 5107>,
			<9623 8154 7133 5439 5146 5107>,
			<9623 8154 7133 5439 5146 5107>;
	};

};
